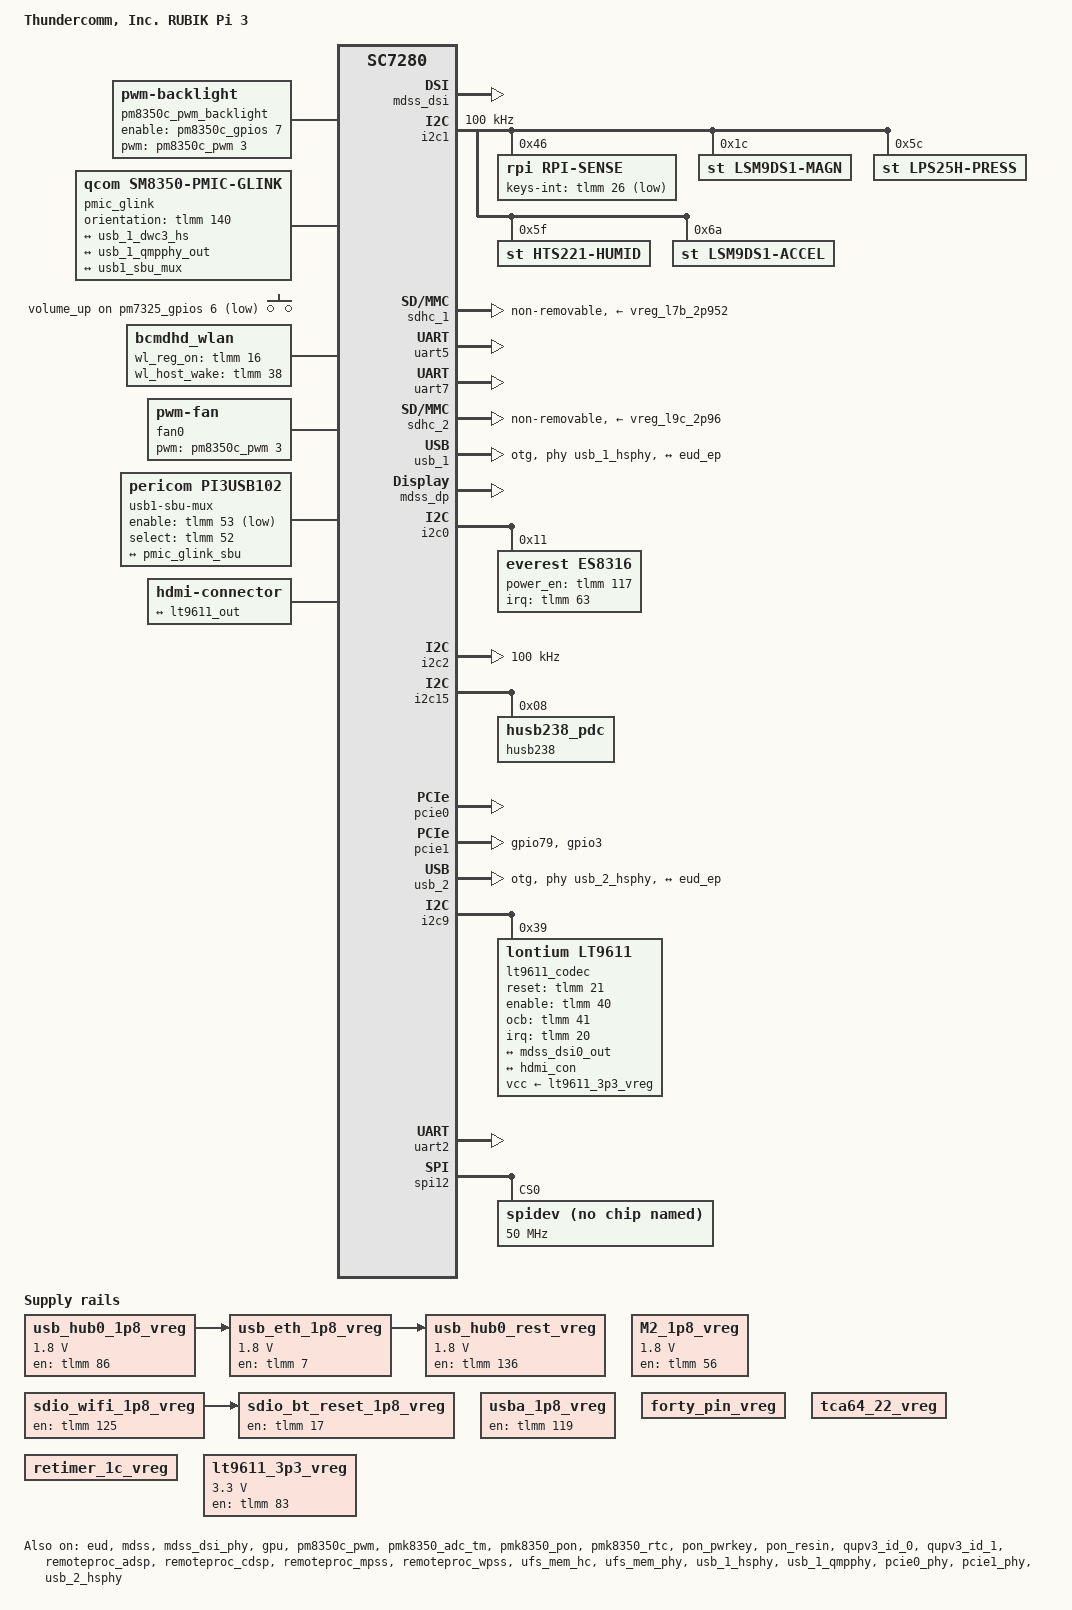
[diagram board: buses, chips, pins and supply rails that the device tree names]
// SPDX-License-Identifier: BSD-3-Clause
/*
 * Copyright (c) 2024, Thundercomm All rights reserved.
 */
#define PM7250B_SID 8
#define PM7250B_SID1 9

#include <dt-bindings/iio/qcom,spmi-adc7-pm7325.h>
#include <dt-bindings/iio/qcom,spmi-adc7-pmk8350.h>
#include <dt-bindings/input/linux-event-codes.h>
#include <dt-bindings/leds/common.h>
#include <dt-bindings/pinctrl/qcom,pmic-gpio.h>
#include <dt-bindings/regulator/qcom,rpmh-regulator.h>
#include "qcm6490.dtsi"
#include "pm7250b.dtsi"
#include "pm7325.dtsi"
#include "pm8350c.dtsi"
#include "pmk8350.dtsi"
#include "qcm6490-addons.dtsi"

/ {
	aliases {
		serial0 = &uart5;
		bluetooth0 = &bluetooth;
	};

	pm8350c_pwm_backlight: backlight {
		compatible = "pwm-backlight";
		pwms = <&pm8350c_pwm 3 65535>;
		enable-gpios = <&pm8350c_gpios 7 GPIO_ACTIVE_HIGH>;
		pinctrl-0 = <&pmic_lcd_bl_en>;
		pinctrl-names = "default";
	};

	chosen {
		stdout-path = "serial0:115200n8";
	};

	lcd_disp_bias: regulator-lcd-disp-bias {
		compatible = "regulator-fixed";
		regulator-name = "lcd_disp_bias";
		regulator-min-microvolt = <5500000>;
		regulator-max-microvolt = <5500000>;
		gpio = <&pm7250b_gpios 2 GPIO_ACTIVE_HIGH>;
		enable-active-high;
		pinctrl-0 = <&lcd_disp_bias_en>;
		pinctrl-names = "default";
	};

	pmic-glink {
		compatible = "qcom,sm8350-pmic-glink", "qcom,pmic-glink";
		#address-cells = <1>;
		#size-cells = <0>;
		orientation-gpios = <&tlmm 140 GPIO_ACTIVE_HIGH>;
		qcom,thermal-mitigation = <3000000 1500000 1000000 500000>;

		connector@0 {
			compatible = "usb-c-connector";
			reg = <0>;
			power-role = "dual";
			data-role = "dual";

			ports {
				#address-cells = <1>;
				#size-cells = <0>;

				port@0 {
					reg = <0>;

					pmic_glink_hs_in: endpoint {
						remote-endpoint = <&eud_con>;
					};
				};

				port@1 {
					reg = <1>;

					pmic_glink_ss_in: endpoint {
						remote-endpoint = <&usb_1_qmpphy_out>;
					};
				};

				port@2 {
					reg = <2>;

					pmic_glink_sbu: endpoint {
						remote-endpoint = <&fsa4480_sbu_mux>;
					};
				};
			};
		};
	};

	sound: sound {
		compatible = "qcom,qcm6490-sndcard";
		model = "qcm6490-idp-snd-card";

		// audio-routing =
		// 	"SpkrLeft IN", "WSA_SPK1 OUT",
		// 	"SpkrRight IN", "WSA_SPK2 OUT",
		// 	"IN1_HPHL", "HPHL_OUT",
		// 	"IN2_HPHR", "HPHR_OUT",
		// 	"AMIC2", "MIC BIAS2",
		// 	"TX DMIC0", "MIC BIAS1",
		// 	"TX DMIC1", "MIC BIAS2",
		// 	"TX DMIC2", "MIC BIAS3",
		// 	"TX SWR_ADC1", "ADC2_OUTPUT",
		// 	"VA DMIC0", "VA MIC BIAS3",
		// 	"VA DMIC1", "VA MIC BIAS3",
		// 	"VA DMIC2", "VA MIC BIAS1",
		// 	"VA DMIC3", "VA MIC BIAS1";

			#address-cells = <1>;
			#size-cells = <0>;

		wsa-dai-link {
			link-name = "CODEC_DMA-LPAIF_WSA-RX-0";

			cpu {
				sound-dai = <&q6apmbedai WSA_CODEC_DMA_RX_0>;
			};

			codec {
				sound-dai = <&left_spkr>, <&right_spkr>, <&swr2 0>,
					    <&lpass_wsa_macro 0>;
			};
		};

		wcd-playback-dai-link {
			link-name = "CODEC_DMA-LPAIF_RXTX-RX-0";

			cpu {
				sound-dai = <&q6apmbedai RX_CODEC_DMA_RX_0>;
			};

			codec {
				sound-dai = <&wcd9370 0>, <&swr0 0>, <&lpass_rx_macro 0>;
			};
		};

		wcd-capture-dai-link {
			link-name = "CODEC_DMA-LPAIF_RXTX-TX-3";

			cpu {
				sound-dai = <&q6apmbedai TX_CODEC_DMA_TX_3>;
			};

			codec {
				sound-dai = <&wcd9370 1>, <&swr1 0>, <&lpass_tx_macro 0>;
			};
		};

		va-dai-link {
			link-name = "CODEC_DMA-LPAIF_VA-TX-0";

			cpu {
				sound-dai = <&q6apmbedai VA_CODEC_DMA_TX_0>;
			};

			codec {
				sound-dai = <&lpass_va_macro 0>;
			};
		};

		vi-feedback-dai-link {
			link-name = "CODEC_DMA-LPAIF_WSA-TX-0";

			cpu {
				sound-dai = <&q6apmbedai WSA_CODEC_DMA_TX_0>;
			};

			codec {
				sound-dai = <&swr2 6>, <&lpass_wsa_macro 2>;
			};
		};
	};

	thermal-zones {
		quiet-thermal {
			polling-delay-passive = <0>;
			polling-delay = <0>;
			thermal-sensors = <&pmk8350_adc_tm 1>;

			trips {
				active-config0 {
					temperature = <125000>;
					hysteresis = <1000>;
					type = "passive";
				};
			};
		};

		sdm-skin-thermal {
			polling-delay-passive = <0>;
			polling-delay = <0>;
			thermal-sensors = <&pmk8350_adc_tm 3>;

			trips {
				active-config0 {
					temperature = <125000>;
					hysteresis = <1000>;
					type = "passive";
				};
			};
		};

		xo-thermal {
			polling-delay-passive = <0>;
			polling-delay = <0>;
			thermal-sensors = <&pmk8350_adc_tm 0>;

			trips {
				active-config0 {
					temperature = <125000>;
					hysteresis = <1000>;
					type = "passive";
				};
			};
		};
	};

	wcd9370: audio-codec-0 {
		compatible = "qcom,wcd9370-codec";

		pinctrl-names = "default", "sleep";
		pinctrl-0 = <&wcd_reset_n>;
		pinctrl-1 = <&wcd_reset_n_sleep>;

		reset-gpios = <&tlmm 83 GPIO_ACTIVE_LOW>;

		vdd-buck-supply = <&vreg_l17b_1p7>;
		vdd-rxtx-supply = <&vreg_l18b_1p8>;
		vdd-px-supply = <&vreg_l18b_1p8>;
		vdd-mic-bias-supply = <&vreg_bob_3p296>;

		qcom,micbias1-microvolt = <1800000>;
		qcom,micbias2-microvolt = <1800000>;
		qcom,micbias3-microvolt = <1800000>;

		qcom,rx-device = <&wcd937x_rx>;
		qcom,tx-device = <&wcd937x_tx>;

		#sound-dai-cells = <1>;
	};

	gpio-keys {
		compatible = "gpio-keys";
		label = "gpio-keys";

		pinctrl-names = "default";
		pinctrl-0 = <&key_vol_up_default>;

		key-volume-up {
			label = "volume_up";
			gpios = <&pm7325_gpios 6 GPIO_ACTIVE_LOW>;
			linux,input-type = <1>;
			linux,code = <KEY_VOLUMEUP>;
			wakeup-source;
			debounce-interval = <15>;
			linux,can-disable;
		};
	};
};

&apps_rsc {
	regulators-0 {
		compatible = "qcom,pm7325-rpmh-regulators";
		qcom,pmic-id = "b";

		vreg_s1b_1p872: smps1 {
			regulator-name = "vreg_s1b_1p872";
			regulator-min-microvolt = <1856000>;
			regulator-max-microvolt = <2040000>;
		};

		vreg_s7b_0p972: smps7 {
			regulator-name = "vreg_s7b_0p972";
			regulator-min-microvolt = <535000>;
			regulator-max-microvolt = <1120000>;
		};

		vreg_s8b_1p272: smps8 {
			regulator-name = "vreg_s8b_1p272";
			regulator-min-microvolt = <1256000>;
			regulator-max-microvolt = <1500000>;
			regulator-initial-mode = <RPMH_REGULATOR_MODE_RET>;
		};

		vreg_l1b_0p912: ldo1 {
			regulator-name = "vreg_l1b_0p912";
			regulator-min-microvolt = <912000>;
			regulator-max-microvolt = <925000>;
			regulator-initial-mode = <RPMH_REGULATOR_MODE_HPM>;
		};

		vreg_l2b_3p072: ldo2 {
			regulator-name = "vreg_l2b_3p072";
			regulator-min-microvolt = <2700000>;
			regulator-max-microvolt = <3544000>;
			regulator-initial-mode = <RPMH_REGULATOR_MODE_HPM>;
		};

		vreg_l6b_1p2: ldo6 {
			regulator-name = "vreg_l6b_1p2";
			regulator-min-microvolt = <1140000>;
			regulator-max-microvolt = <1260000>;
			regulator-initial-mode = <RPMH_REGULATOR_MODE_HPM>;
		};

		vreg_l7b_2p952: ldo7 {
			regulator-name = "vreg_l7b_2p952";
			regulator-min-microvolt = <2960000>;
			regulator-max-microvolt = <2960000>;
			regulator-initial-mode = <RPMH_REGULATOR_MODE_HPM>;
		};

		vreg_l8b_0p904: ldo8 {
			regulator-name = "vreg_l8b_0p904";
			regulator-min-microvolt = <870000>;
			regulator-max-microvolt = <970000>;
			regulator-initial-mode = <RPMH_REGULATOR_MODE_HPM>;
		};

		vreg_l9b_1p2: ldo9 {
			regulator-name = "vreg_l9b_1p2";
			regulator-min-microvolt = <1080000>;
			regulator-max-microvolt = <1304000>;
			regulator-initial-mode = <RPMH_REGULATOR_MODE_HPM>;
		};

		vreg_l11b_1p504: ldo11 {
			regulator-name = "vreg_l11b_1p504";
			regulator-min-microvolt = <1504000>;
			regulator-max-microvolt = <2000000>;
			regulator-initial-mode = <RPMH_REGULATOR_MODE_HPM>;
		};

		vreg_l12b_0p751: ldo12 {
			regulator-name = "vreg_l12b_0p751";
			regulator-min-microvolt = <751000>;
			regulator-max-microvolt = <824000>;
			regulator-initial-mode = <RPMH_REGULATOR_MODE_HPM>;
		};

		vreg_l13b_0p53: ldo13 {
			regulator-name = "vreg_l13b_0p53";
			regulator-min-microvolt = <530000>;
			regulator-max-microvolt = <824000>;
			regulator-initial-mode = <RPMH_REGULATOR_MODE_HPM>;
		};

		vreg_l14b_1p08: ldo14 {
			regulator-name = "vreg_l14b_1p08";
			regulator-min-microvolt = <1080000>;
			regulator-max-microvolt = <1304000>;
			regulator-initial-mode = <RPMH_REGULATOR_MODE_HPM>;
		};

		vreg_l15b_0p765: ldo15 {
			regulator-name = "vreg_l15b_0p765";
			regulator-min-microvolt = <765000>;
			regulator-max-microvolt = <1020000>;
			regulator-initial-mode = <RPMH_REGULATOR_MODE_HPM>;
		};

		vreg_l16b_1p1: ldo16 {
			regulator-name = "vreg_l16b_1p1";
			regulator-min-microvolt = <1100000>;
			regulator-max-microvolt = <1300000>;
			regulator-initial-mode = <RPMH_REGULATOR_MODE_HPM>;
		};

		vreg_l17b_1p7: ldo17 {
			regulator-name = "vreg_l17b_1p7";
			regulator-min-microvolt = <1700000>;
			regulator-max-microvolt = <1900000>;
			regulator-initial-mode = <RPMH_REGULATOR_MODE_HPM>;
		};

		vreg_l18b_1p8: ldo18 {
			regulator-name = "vreg_l18b_1p8";
			regulator-min-microvolt = <1800000>;
			regulator-max-microvolt = <2000000>;
			regulator-initial-mode = <RPMH_REGULATOR_MODE_HPM>;
		};

		vreg_l19b_1p8: ldo19 {
			regulator-name = "vreg_l19b_1p8";
			regulator-min-microvolt = <1800000>;
			regulator-max-microvolt = <1800000>;
			regulator-initial-mode = <RPMH_REGULATOR_MODE_HPM>;
		};
	};

	regulators-1 {
		compatible = "qcom,pm8350c-rpmh-regulators";
		qcom,pmic-id = "c";

		vreg_s1c_2p19: smps1 {
			regulator-name = "vreg_s1c_2p19";
			regulator-min-microvolt = <2190000>;
			regulator-max-microvolt = <2210000>;
			regulator-initial-mode = <RPMH_REGULATOR_MODE_HPM>;
		};

		vreg_s9c_1p084: smps9 {
			regulator-name = "vreg_s9c_1p084";
			regulator-min-microvolt = <1010000>;
			regulator-max-microvolt = <1170000>;
			regulator-initial-mode = <RPMH_REGULATOR_MODE_HPM>;
		};

		vreg_l1c_1p8: ldo1 {
			regulator-name = "vreg_l1c_1p8";
			regulator-min-microvolt = <1800000>;
			regulator-max-microvolt = <1980000>;
			regulator-initial-mode = <RPMH_REGULATOR_MODE_HPM>;
		};

		vreg_l2c_1p62: ldo2 {
			regulator-name = "vreg_l2c_1p62";
			regulator-min-microvolt = <1620000>;
			regulator-max-microvolt = <1980000>;
			regulator-initial-mode = <RPMH_REGULATOR_MODE_HPM>;
		};

		vreg_l3c_2p8: ldo3 {
			regulator-name = "vreg_l3c_2p8";
			regulator-min-microvolt = <2800000>;
			regulator-max-microvolt = <3540000>;
			regulator-initial-mode = <RPMH_REGULATOR_MODE_HPM>;
		};

		vreg_l4c_1p62: ldo4 {
			regulator-name = "vreg_l4c_1p62";
			regulator-min-microvolt = <1620000>;
			regulator-max-microvolt = <3300000>;
			regulator-initial-mode = <RPMH_REGULATOR_MODE_HPM>;
		};

		vreg_l5c_1p62: ldo5 {
			regulator-name = "vreg_l5c_1p62";
			regulator-min-microvolt = <1620000>;
			regulator-max-microvolt = <3300000>;
			regulator-initial-mode = <RPMH_REGULATOR_MODE_HPM>;
		};

		vreg_l6c_2p96: ldo6 {
			regulator-name = "vreg_l6c_2p96";
			regulator-min-microvolt = <1800000>;
			regulator-max-microvolt = <2950000>;
			regulator-initial-mode = <RPMH_REGULATOR_MODE_HPM>;
		};

		vreg_l7c_3p0: ldo7 {
			regulator-name = "vreg_l7c_3p0";
			regulator-min-microvolt = <3000000>;
			regulator-max-microvolt = <3544000>;
			regulator-initial-mode = <RPMH_REGULATOR_MODE_HPM>;
		};

		vreg_l8c_1p62: ldo8 {
			regulator-name = "vreg_l8c_1p62";
			regulator-min-microvolt = <1620000>;
			regulator-max-microvolt = <2000000>;
			regulator-initial-mode = <RPMH_REGULATOR_MODE_HPM>;
		};

		vreg_l9c_2p96: ldo9 {
			regulator-name = "vreg_l9c_2p96";
			regulator-min-microvolt = <2960000>;
			regulator-max-microvolt = <2960000>;
			regulator-initial-mode = <RPMH_REGULATOR_MODE_HPM>;
		};

		vreg_l10c_0p88: ldo10 {
			regulator-name = "vreg_l10c_0p88";
			regulator-min-microvolt = <880000>;
			regulator-max-microvolt = <1050000>;
			regulator-initial-mode = <RPMH_REGULATOR_MODE_HPM>;
		};

		vreg_l11c_2p8: ldo11 {
			regulator-name = "vreg_l11c_2p8";
			regulator-min-microvolt = <2800000>;
			regulator-max-microvolt = <3544000>;
			regulator-initial-mode = <RPMH_REGULATOR_MODE_HPM>;
		};

		vreg_l12c_1p65: ldo12 {
			regulator-name = "vreg_l12c_1p65";
			regulator-min-microvolt = <1650000>;
			regulator-max-microvolt = <2000000>;
			regulator-initial-mode = <RPMH_REGULATOR_MODE_HPM>;
		};

		vreg_l13c_2p7: ldo13 {
			regulator-name = "vreg_l13c_2p7";
			regulator-min-microvolt = <2700000>;
			regulator-max-microvolt = <3544000>;
			regulator-initial-mode = <RPMH_REGULATOR_MODE_HPM>;
		};

		vreg_bob_3p296: bob {
			regulator-name = "vreg_bob_3p296";
			regulator-min-microvolt = <3008000>;
			regulator-max-microvolt = <3960000>;
		};
	};
};

&eud {
	usb-role-switch;
	status = "okay";
};

&eud_con {
	remote-endpoint = <&pmic_glink_hs_in>;
};

&eud_ep {
	remote-endpoint = <&usb_1_dwc3_hs>;
};

&mdss {
	status = "okay";
};

&mdss_dsi {
	vdda-supply = <&vreg_l6b_1p2>;
	status = "okay";

	panel@0 {
		compatible = "novatek,nt36672e";
		reg = <0>;

		reset-gpios = <&tlmm 44 GPIO_ACTIVE_HIGH>;

		vddi-supply = <&vreg_l8c_1p62>;
		avdd-supply = <&lcd_disp_bias>;
		avee-supply = <&lcd_disp_bias>;

		backlight = <&pm8350c_pwm_backlight>;

		port {
			panel0_in: endpoint {
				remote-endpoint = <&mdss_dsi0_out>;
			};
		};
	};
};

&mdss_dsi0_out {
	remote-endpoint = <&panel0_in>;
	data-lanes = <0 1 2 3>;
};

&mdss_dsi_phy {
	vdds-supply = <&vreg_l10c_0p88>;
	status = "okay";
};

&gpi_dma0 {
	status = "okay";
};

&gpi_dma1 {
	status = "okay";
};

&i2c1 {
	clock-frequency = <100000>;
	status = "okay";

	typec-mux@42 {
		compatible = "fcs,fsa4480";
		reg = <0x42>;
		interrupts-extended = <&tlmm 2 IRQ_TYPE_LEVEL_LOW>;
		vcc-supply = <&vreg_bob_3p296>;
		mode-switch;
		orientation-switch;
		svid = /bits/ 16 <0xff01>;

		ports {
			#address-cells = <1>;
			#size-cells = <0>;

			port@0 {
				reg = <0>;

				fsa4480_sbu_mux: endpoint {
					remote-endpoint = <&pmic_glink_sbu>;
				};
			};
		};
	};
};

&lpasscc {
	status = "disabled";
};

&lpass_dmic01_clk {
	drive-strength = <8>;
	bias-disable;
};

&lpass_dmic01_data {
	bias-pull-down;
};

&lpass_dmic23_clk {
	drive-strength = <8>;
	bias-disable;
};

&lpass_dmic23_data {
	bias-pull-down;
};

&lpass_rx_swr_clk {
	drive-strength = <2>;
	slew-rate = <1>;
	bias-disable;
};

&lpass_rx_swr_data {
	drive-strength = <2>;
	slew-rate = <1>;
	bias-bus-hold;
};

&lpass_tx_swr_clk {
	drive-strength = <2>;
	slew-rate = <1>;
	bias-disable;
};

&lpass_tx_swr_data {
	drive-strength = <2>;
	slew-rate = <1>;
	bias-bus-hold;
};

&lpass_wsa_swr_clk {
	drive-strength = <2>;
	slew-rate = <1>;
	bias-disable;
};

&lpass_wsa_swr_data {
	drive-strength = <2>;
	slew-rate = <1>;
	bias-bus-hold;
};

&pm7325_gpios {
	key_vol_up_default: key-vol-up-state {
		pins = "gpio6";
		function = "normal";
		input-enable;
		bias-pull-up;
		power-source = <0>;
		qcom,drive-strength = <3>;
	};
};

&gpu {
	status = "okay";
};

&gpu_zap_shader {
	firmware-name = "qcom/qcm6490/a660_zap.mbn";
};

&pm7250b_gpios {
	lcd_disp_bias_en: lcd-disp-bias-en-state {
		pins = "gpio2";
		function = "func1";
		bias-disable;
		qcom,drive-strength = <PMIC_GPIO_STRENGTH_LOW>;
		input-disable;
		output-enable;
		power-source = <0>;
	};
};

&pm8350c_gpios {
	pmic_lcd_bl_en: pmic-lcd-bl-en-state {
		pins = "gpio7";
		function = "normal";
		bias-disable;
		qcom,drive-strength = <PMIC_GPIO_STRENGTH_LOW>;
		output-low;
		power-source = <0>;
	};

	pmic_lcd_bl_pwm: pmic-lcd-bl-pwm-state {
		pins = "gpio8";
		function = "func1";
		bias-disable;
		qcom,drive-strength = <PMIC_GPIO_STRENGTH_LOW>;
		output-low;
		power-source = <0>;
	};
};

&pm8350c_pwm {
	#address-cells = <1>;
	#size-cells = <0>;
	pinctrl-0 = <&pmic_lcd_bl_pwm>;
	pinctrl-names = "default";
	status = "okay";

	led@1 {
		reg = <1>;
		color = <LED_COLOR_ID_RED>;
		label = "red";
	};

	led@2 {
		reg = <2>;
		color = <LED_COLOR_ID_GREEN>;
		label = "green";
	};

	led@3 {
		reg = <3>;
		color = <LED_COLOR_ID_BLUE>;
		label = "blue";
	};
};

&pmk8350_adc_tm {
	status = "okay";

	xo-therm@0 {
		reg = <0>;
		io-channels = <&pmk8350_vadc PMK8350_ADC7_AMUX_THM1_100K_PU>;
		qcom,ratiometric;
		qcom,hw-settle-time-us = <200>;
	};

	quiet-therm@1 {
		reg = <1>;
		io-channels = <&pmk8350_vadc PM7325_ADC7_AMUX_THM1_100K_PU>;
		qcom,ratiometric;
		qcom,hw-settle-time-us = <200>;
	};

	sdm-skin-therm@3 {
		reg = <3>;
		io-channels = <&pmk8350_vadc PM7325_ADC7_AMUX_THM3_100K_PU>;
		qcom,ratiometric;
		qcom,hw-settle-time-us = <200>;
	};
};

&pmk8350_pon {
	status = "okay";
};

&pmk8350_rtc {
	status = "okay";
};

&pmk8350_vadc {
	channel@44 {
		reg = <PMK8350_ADC7_AMUX_THM1_100K_PU>;
		label = "xo_therm";
		qcom,hw-settle-time = <200>;
		qcom,pre-scaling = <1 1>;
		qcom,ratiometric;
	};

	channel@144 {
		reg = <PM7325_ADC7_AMUX_THM1_100K_PU>;
		qcom,ratiometric;
		qcom,hw-settle-time = <200>;
		qcom,pre-scaling = <1 1>;
		label = "pm7325_quiet_therm";
	};

	channel@146 {
		reg = <PM7325_ADC7_AMUX_THM3_100K_PU>;
		qcom,ratiometric;
		qcom,hw-settle-time = <200>;
		qcom,pre-scaling = <1 1>;
		label = "pm7325_sdm_skin_therm";
	};

	pmk8350-die-temp@3 {
		reg = <PMK8350_ADC7_DIE_TEMP>;
		label = "pmk8350_die_temp";
		qcom,pre-scaling = <1 1>;
	};
};

&pon_pwrkey {
	status = "okay";
};

&pon_resin {
	linux,code = <KEY_VOLUMEDOWN>;
	status = "okay";
};

&qup_uart5_rx {
	drive-strength = <2>;
	bias-pull-up;
};

&qup_uart5_tx {
	drive-strength = <2>;
	bias-disable;
};

&qup_uart7_cts {
	/*
	 * Configure a bias-bus-hold on CTS to lower power
	 * usage when Bluetooth is turned off. Bus hold will
	 * maintain a low power state regardless of whether
	 * the Bluetooth module drives the pin in either
	 * direction or leaves the pin fully unpowered.
	 */
	bias-bus-hold;
};

&qup_uart7_rts {
	/* We'll drive RTS, so no pull */
	drive-strength = <2>;
	bias-disable;
};

&qup_uart7_rx {
	/*
	 * Configure a pull-up on RX. This is needed to avoid
	 * garbage data when the TX pin of the Bluetooth module is
	 * in tri-state (module powered off or not driving the
	 * signal yet).
	 */
	bias-pull-up;
};

&qup_uart7_tx {
	/* We'll drive TX, so no pull */
	drive-strength = <2>;
	bias-disable;
};

&qupv3_id_0 {
	status = "okay";
};

&qupv3_id_1 {
	status = "okay";
};

&remoteproc_adsp {
	firmware-name = "qcom/qcm6490/adsp.mdt";
	status = "okay";
};

&remoteproc_cdsp {
	firmware-name = "qcom/qcm6490/cdsp.mdt";
	status = "okay";
};

&remoteproc_mpss {
	firmware-name = "qcom/qcm6490/modem.mdt";
	status = "okay";
};

&remoteproc_wpss {
	firmware-name = "qcom/qcm6490/wpss.mdt";
	status = "okay";
};

&sdc1_clk {
	bias-disable;
	drive-strength = <16>;
};

&sdc1_cmd {
	bias-pull-up;
	drive-strength = <10>;
};

&sdc1_data {
	bias-pull-up;
	drive-strength = <10>;
};

&sdc1_rclk {
	bias-pull-down;
};

&swr2 {
	qcom,din-ports = <0>;
	qcom,dout-ports = <8>;

	left_spkr: speaker@0,1 {
		compatible = "sdw10217020200";
		reg = <0 1>;
		powerdown-gpios = <&tlmm 63 GPIO_ACTIVE_LOW>;
		#sound-dai-cells = <0>;
		sound-name-prefix = "SpkrLeft";
		#thermal-sensor-cells = <0>;
		vdd-supply = <&vreg_l18b_1p8>;
		qcom,port-mapping = <1 2 3 7>;
	};

	right_spkr: speaker@0,2 {
		compatible = "sdw10217020200";
		reg = <0 2>;
		powerdown-gpios = <&tlmm 62 GPIO_ACTIVE_LOW>;
		#sound-dai-cells = <0>;
		sound-name-prefix = "SpkrRight";
		#thermal-sensor-cells = <0>;
		vdd-supply = <&vreg_l18b_1p8>;
		qcom,port-mapping = <4 5 6 8>;
	};
};

&sdhc_1 {
	non-removable;
	no-sd;
	no-sdio;

	vmmc-supply = <&vreg_l7b_2p952>;
	vqmmc-supply = <&vreg_l19b_1p8>;

	status = "okay";
};

&swr0 {
	wcd937x_rx: codec@0,4 {
		compatible = "sdw20217010a00";
		reg = <0 4>;
		qcom,rx-port-mapping = <1 2 3 4 5>;
	};
};

&swr1 {
	wcd937x_tx: codec@0,3 {
		compatible = "sdw20217010a00";
		reg = <0 3>;
		qcom,tx-port-mapping = <1 1 2 3>;
	};
};

&sdc2_clk {
	bias-disable;
	drive-strength = <16>;
};

&sdc2_cmd {
	bias-pull-up;
	drive-strength = <10>;
};

&sdc2_data {
	bias-pull-up;
	drive-strength = <10>;
};

&tlmm {
	bt_en: bt-en-state {
		pins = "gpio85";
		function = "gpio";
		output-low;
		bias-disable;
	};

	qup_uart7_sleep_cts: qup-uart7-sleep-cts-state {
		pins = "gpio28";
		function = "gpio";
		/*
		 * Configure a bias-bus-hold on CTS to lower power
		 * usage when Bluetooth is turned off. Bus hold will
		 * maintain a low power state regardless of whether
		 * the Bluetooth module drives the pin in either
		 * direction or leaves the pin fully unpowered.
		 */
		bias-bus-hold;
	};

	qup_uart7_sleep_rts: qup-uart7-sleep-rts-state {
		pins = "gpio29";
		function = "gpio";
		/*
		 * Configure pull-down on RTS. As RTS is active low
		 * signal, pull it low to indicate the BT SoC that it
		 * can wakeup the system anytime from suspend state by
		 * pulling RX low (by sending wakeup bytes).
		 */
		bias-pull-down;
	};

	qup_uart7_sleep_rx: qup-uart7-sleep-rx-state {
		pins = "gpio31";
		function = "gpio";
		/*
		 * Configure a pull-up on RX. This is needed to avoid
		 * garbage data when the TX pin of the Bluetooth module
		 * is floating which may cause spurious wakeups.
		 */
		bias-pull-up;
	};

	qup_uart7_sleep_tx: qup-uart7-sleep-tx-state {
		pins = "gpio30";
		function = "gpio";
		/*
		 * Configure pull-up on TX when it isn't actively driven
		 * to prevent BT SoC from receiving garbage during sleep.
		 */
		bias-pull-up;
	};

	sd_cd: sd-cd-state {
		pins = "gpio91";
		function = "gpio";
		bias-pull-up;
	};

	sw_ctrl: sw-ctrl-state {
		pins = "gpio86";
		function = "gpio";
		bias-pull-down;
	};

	wcd_reset_n: wcd-reset-n-state {
		pins = "gpio83";
		function = "gpio";
		drive-strength = <8>;
	};

	wcd_reset_n_sleep: wcd-reset-n-sleep-state {
		pins = "gpio83";
		function = "gpio";
		drive-strength = <8>;
		bias-disable;
	};
};

&uart5 {
	compatible = "qcom,geni-debug-uart";
	status = "okay";
};

&uart7 {
	status = "okay";
	/delete-property/interrupts;
	interrupts-extended = <&intc GIC_SPI 608 IRQ_TYPE_LEVEL_HIGH>,
				<&tlmm 31 IRQ_TYPE_EDGE_FALLING>;
	pinctrl-names = "default", "sleep";
	pinctrl-1 = <&qup_uart7_sleep_cts>, <&qup_uart7_sleep_rts>,
			<&qup_uart7_sleep_tx>, <&qup_uart7_sleep_rx>;

	bluetooth: bluetooth {
		compatible = "qcom,wcn6750-bt";
		pinctrl-names = "default";
		pinctrl-0 = <&bt_en>, <&sw_ctrl>;
		enable-gpios = <&tlmm 85 GPIO_ACTIVE_HIGH>;
		swctrl-gpios = <&tlmm 86 GPIO_ACTIVE_HIGH>;
		vddaon-supply = <&vreg_s7b_0p972>;
		vddbtcxmx-supply = <&vreg_s7b_0p972>;
		vddrfacmn-supply = <&vreg_s7b_0p972>;
		vddrfa0p8-supply = <&vreg_s7b_0p972>;
		vddrfa1p7-supply = <&vreg_s1b_1p872>;
		vddrfa1p2-supply = <&vreg_s8b_1p272>;
		vddrfa2p2-supply = <&vreg_s1c_2p19>;
		vddasd-supply = <&vreg_l11c_2p8>;
		max-speed = <3200000>;
	};
};

&ufs_mem_hc {
	reset-gpios = <&tlmm 175 GPIO_ACTIVE_LOW>;
	vcc-supply = <&vreg_l7b_2p952>;
	vcc-max-microamp = <800000>;
	vccq-supply = <&vreg_l9b_1p2>;
	vccq-max-microamp = <900000>;
	vccq2-supply = <&vreg_l9b_1p2>;
	vccq2-max-microamp = <900000>;

	status = "okay";
};

&ufs_mem_phy {
	vdda-phy-supply = <&vreg_l10c_0p88>;
	vdda-pll-supply = <&vreg_l6b_1p2>;

	status = "okay";
};

&sdhc_2 {
	status = "okay";

	pinctrl-0 = <&sdc2_clk>, <&sdc2_cmd>, <&sdc2_data>, <&sd_cd>;
	pinctrl-1 = <&sdc2_clk_sleep>, <&sdc2_cmd_sleep>, <&sdc2_data_sleep>, <&sd_cd>;

	vmmc-supply = <&vreg_l9c_2p96>;
	vqmmc-supply = <&vreg_l6c_2p96>;

	cd-gpios = <&tlmm 91 GPIO_ACTIVE_LOW>;
};

/delete-node/ &usb_1_dwc3;

&usb_1 {

	reg = <0x0 0x0a600000 0x0 0x200000>;

	interrupts-extended = <&intc GIC_SPI 133 IRQ_TYPE_LEVEL_HIGH>,
			      <&intc GIC_SPI 131 IRQ_TYPE_LEVEL_HIGH>,
			      <&pdc 14 IRQ_TYPE_LEVEL_HIGH>,
			      <&pdc 15 IRQ_TYPE_EDGE_BOTH>,
			      <&pdc 17 IRQ_TYPE_EDGE_BOTH>;
	interrupt-names = "dwc_usb3",
			  "hs_phy_irq",
			  "dp_hs_phy_irq",
			  "dm_hs_phy_irq",
			  "ss_phy_irq";

	iommus = <&apps_smmu 0xe0 0x0>;
	snps,dis_u2_susphy_quirk;
	snps,dis_enblslpm_quirk;
	phys = <&usb_1_hsphy>, <&usb_1_qmpphy QMP_USB43DP_USB3_PHY>;
	phy-names = "usb2-phy", "usb3-phy";
	maximum-speed = "super-speed";

	dr_mode = "otg";
	usb-role-switch;
	qcom,enable-rt;
	wakeup-source;

	status = "okay";

	ports {
		#address-cells = <1>;
		#size-cells = <0>;


		port@0 {
			reg = <0>;
			usb_1_dwc3_hs: endpoint {
			};
		};
	};
};

&usb_1_dwc3_hs {
	remote-endpoint = <&eud_ep>;
};

&usb_1_hsphy {
	vdda-pll-supply = <&vreg_l10c_0p88>;
	vdda33-supply = <&vreg_l2b_3p072>;
	vdda18-supply = <&vreg_l1c_1p8>;
	qcom,hs-rise-fall-time-bp = <0>;
	qcom,squelch-detector-bp = <(-2090)>;
	qcom,hs-disconnect-bp = <1743>;
	qcom,hs-amplitude-bp = <1780>;
	qcom,hs-crossover-voltage-microvolt = <(-31000)>;
	qcom,hs-output-impedance-micro-ohms = <2600000>;

	status = "okay";
};

&usb_1_qmpphy {
	vdda-phy-supply = <&vreg_l6b_1p2>;
	vdda-pll-supply = <&vreg_l1b_0p912>;

	orientation-switch;
	status = "okay";
};

&usb_1_qmpphy_out {
	remote-endpoint = <&pmic_glink_ss_in>;
};

&vreg_l7b_2p952 {
	/delete-property/regulator-min-microvolt;
	/delete-property/regulator-max-microvolt;
	regulator-allow-set-load;
	regulator-allowed-modes = <RPMH_REGULATOR_MODE_LPM RPMH_REGULATOR_MODE_HPM>;
};

&vreg_l9b_1p2 {
	/delete-property/regulator-min-microvolt;
	/delete-property/regulator-max-microvolt;
	regulator-allow-set-load;
	regulator-allowed-modes = <RPMH_REGULATOR_MODE_LPM RPMH_REGULATOR_MODE_HPM>;
};

/ {
	pmic_glink: pmic-glink {
	};
};

&i2c1 {
	#address-cells = <1>;
	#size-cells = <0>;
	status = "okay";

	pm8008i_chip: pm8008i@8 {
		compatible = "qcom,i2c-pmic";
		reg = <0x8>;
		#address-cells = <1>;
		#size-cells = <0>;

		pinctrl-names = "default";
		pinctrl-0 = <&pm8008i_active>;

		pm8008-chip@900 {
			compatible = "qcom,pm8008-chip";
			reg = <0x900>;

			PM8008I_EN: qcom,pm8008-chip-en {
				regulator-name = "pm8008i-chip-en";
			};
		};
	};

	pm8008i_ldo: pm8008i@9 {
		compatible = "qcom,i2c-pmic";
		reg = <0x9>;
		#address-cells = <1>;
		#size-cells = <0>;

		qcom,pm8008i-regulator {
			compatible = "qcom,pm8008-regulator";
			#address-cells = <1>;
			#size-cells = <0>;

			pm8008_en-supply = <&PM8008I_EN>;
			vdd_l1_l2-supply = <&vreg_s8b_1p272>;
			vdd_l3_l4-supply = <&vreg_bob_3p296>;
			vdd_l5-supply = <&vreg_s1b_1p872>;
			vdd_l6-supply = <&vreg_bob_3p296>;
			vdd_l7-supply = <&vreg_bob_3p296>;

			L1I: PM8008I_L1: regulator@4000 {
				reg = <0x4000>;
				regulator-name = "pm8008i_l1";
				regulator-min-microvolt = <1000000>;
				regulator-max-microvolt = <1200000>;
				qcom,min-dropout-voltage = <160000>;
				qcom,hpm-min-load = <30000>;
			};

			L2I: PM8008I_L2: regulator@4100 {
				reg = <0x4100>;
				regulator-name = "pm8008i_l2";
				regulator-min-microvolt = <950000>;
				regulator-max-microvolt = <1150000>;
				qcom,min-dropout-voltage = <128000>;
				qcom,hpm-min-load = <30000>;
			};

			L3I: PM8008I_L3: regulator@4200 {
				reg = <0x4200>;
				regulator-name = "pm8008i_l3";
				regulator-min-microvolt = <2700000>;
				regulator-max-microvolt = <3000000>;
				qcom,min-dropout-voltage = <144000>;
			};

			L4I: PM8008I_L4: regulator@4300 {
				reg = <0x4300>;
				regulator-name = "pm8008i_l4";
				regulator-min-microvolt = <2700000>;
				regulator-max-microvolt = <2900000>;
				qcom,min-dropout-voltage = <128000>;
			};

			L5I: PM8008I_L5: regulator@4400 {
				reg = <0x4400>;
				regulator-name = "pm8008i_l5";
				regulator-min-microvolt = <1700000>;
				regulator-max-microvolt = <1900000>;
				qcom,min-dropout-voltage = <136000>;
			};

			L6I: PM8008I_L6: regulator@4500 {
				reg = <0x4500>;
				regulator-name = "pm8008i_l6";
				regulator-min-microvolt = <2700000>;
				regulator-max-microvolt = <2900000>;
				qcom,min-dropout-voltage = <128000>;
			};

			L7I: PM8008I_L7: regulator@4600 {
				reg = <0x4600>;
				regulator-name = "pm8008i_l7";
				regulator-min-microvolt = <2700000>;
				regulator-max-microvolt = <3000000>;
				qcom,min-dropout-voltage = <312000>;
			};
		};
	};

	pm8008j_chip: pm8008j@c {
		compatible = "qcom,i2c-pmic";
		reg = <0xc>;
		#address-cells = <1>;
		#size-cells = <0>;

		pinctrl-names = "default";
		pinctrl-0 = <&pm8008j_active>;

		pm8008-chip@900 {
			compatible = "qcom,pm8008-chip";
			reg = <0x900>;

			PM8008J_EN: qcom,pm8008-chip-en {
				regulator-name = "pm8008j-chip-en";
			};
		};
	};

	pm8008j_ldo: pm8008j@d {
		compatible = "qcom,i2c-pmic";
		reg = <0xd>;
		#address-cells = <1>;
		#size-cells = <0>;

		qcom,pm8008j-regulator {
			compatible = "qcom,pm8008-regulator";
			#address-cells = <1>;
			#size-cells = <0>;

			pm8008_en-supply = <&PM8008J_EN>;
			vdd_l1_l2-supply = <&vreg_s8b_1p272>;
			vdd_l3_l4-supply = <&vreg_s1b_1p872>;
			vdd_l5-supply = <&vreg_bob_3p296>;
			vdd_l6-supply = <&vreg_bob_3p296>;
			vdd_l7-supply = <&vreg_bob_3p296>;

			L1J: PM8008J_L1: regulator@4000 {
				reg = <0x4000>;
				regulator-name = "pm8008j_l1";
				regulator-min-microvolt = <950000>;
				regulator-max-microvolt = <1150000>;
				qcom,min-dropout-voltage = <96000>;
				qcom,hpm-min-load = <30000>;
			};

			L2J: PM8008J_L2: regulator@4100 {
				reg = <0x4100>;
				regulator-name = "pm8008j_l2";
				regulator-min-microvolt = <950000>;
				regulator-max-microvolt = <1250000>;
				qcom,min-dropout-voltage = <24000>;
				qcom,hpm-min-load = <30000>;
			};

			L3J: PM8008J_L3: regulator@4200 {
				reg = <0x4200>;
				regulator-name = "pm8008j_l3";
				regulator-min-microvolt = <1460000>;
				regulator-max-microvolt = <1800000>;
				qcom,min-dropout-voltage = <224000>;
			};

			L4J: PM8008J_L4: regulator@4300 {
				reg = <0x4300>;
				regulator-name = "pm8008j_l4";
				regulator-min-microvolt = <1504000>;
				regulator-max-microvolt = <1600000>;
				qcom,min-dropout-voltage = <0>;
			};

			L5J: PM8008J_L5: regulator@4400 {
				reg = <0x4400>;
				regulator-name = "pm8008j_l5";
				regulator-min-microvolt = <2700000>;
				regulator-max-microvolt = <2900000>;
				qcom,min-dropout-voltage = <104000>;
			};

			L6J: PM8008J_L6: regulator@4500 {
				reg = <0x4500>;
				regulator-name = "pm8008j_l6";
				regulator-min-microvolt = <2800000>;
				regulator-max-microvolt = <2800000>;
				qcom,min-dropout-voltage = <112000>;
			};

			L7J: PM8008J_L7: regulator@4600 {
				reg = <0x4600>;
				regulator-name = "pm8008j_l7";
				regulator-min-microvolt = <3000000>;
				regulator-max-microvolt = <3544000>;
				qcom,min-dropout-voltage = <96000>;
			};
		};
	};
};

&pm8350c_gpios {
	pm8008i-reset-state {
		pm8008i_active: pm8008i-active-pins {
			pins = "gpio3";
			function = "normal";
			bias-disable;
			output-high;
			power-source = <0>;
		};
	};

	pm8008j-reset-state {
		pm8008j_active: pm8008j-active-pins {
			pins = "gpio4";
			function = "normal";
			bias-disable;
			output-high;
			power-source = <0>;
		};
	};
};

&q6apmbedai {
	qcom,prmcc_clk = <&q6prmcc>;
};

&sound {
	pinctrl-names = "default", "stub_aif1_active", "stub_aif1_sleep";
	pinctrl-0 = <&mi2s0_data0_sleep>, <&mi2s0_data1_sleep>, <&mi2s0_mclk_sleep>,
				<&mi2s0_sclk_sleep>, <&mi2s0_ws_sleep>;
	pinctrl-1 = <&mi2s0_data0>, <&mi2s0_data1>, <&mi2s0_mclk>,
				<&mi2s0_sclk>, <&mi2s0_ws>;
	pinctrl-2 = <&mi2s0_data0_sleep>, <&mi2s0_data1_sleep>, <&mi2s0_mclk_sleep>,
				<&mi2s0_sclk_sleep>, <&mi2s0_ws_sleep>;

	mi2s-capture-dai-link {
		link-name = "MI2S-LPAIF-TX-PRIMARY";

		cpu {
			sound-dai = <&q6apmbedai PRIMARY_MI2S_TX>;
		};

		codec {
			sound-dai = <&msm_stub_codec 1>;
		};
	};

	mi2s-playback-dai-link {
		link-name = "MI2S-LPAIF-RX-PRIMARY";

		cpu {
			sound-dai = <&q6apmbedai PRIMARY_MI2S_RX>;
		};

		codec {
			sound-dai = <&msm_stub_codec 0>;
		};
	};

	tdm-capture-dai-link {
		link-name = "TDM-LPAIF-TX-PRIMARY";

		cpu {
			sound-dai = <&q6apmbedai PRIMARY_TDM_TX_0>;
		};

		codec {
			sound-dai = <&msm_stub_codec 1>;
		};
	};

	tdm-playback-dai-link {
		link-name = "TDM-LPAIF-RX-PRIMARY";

		cpu {
			sound-dai = <&q6apmbedai PRIMARY_TDM_RX_0>;
		};

		codec {
			sound-dai = <&msm_stub_codec 0>;
		};
	};
};

&tlmm {
	mi2s0_data0_sleep: mi2s0-data0-sleep {
		pins = "gpio98";
		function = "gpio";
		drive-strength = <2>;
		bias-pull-down;
		input-enable;
	};

	mi2s0_data1_sleep: mi2s0-data1-sleep {
		pins = "gpio99";
		function = "gpio";
		drive-strength = <2>;
		bias-pull-down;
		input-enable;
	};

	mi2s0_mclk_sleep: mi2s0-mclk-sleep {
		pins = "gpio96";
		function = "gpio";
		drive-strength = <2>;
		bias-pull-down;
		input-enable;
	};

	mi2s0_sclk_sleep: mi2s0-sclk-sleep {
		pins = "gpio97";
		function = "gpio";
		drive-strength = <2>;
		bias-pull-down;
		input-enable;
	};

	mi2s0_ws_sleep: mi2s0-ws-sleep {
		pins = "gpio100";
		function = "gpio";
		drive-strength = <2>;
		bias-pull-down;
		input-enable;
	};
};

/ {
	chosen {
		display_bootargs = "";
		enable_logo_Partition = "splash";
		stdout-path = "serial0:115200n8";
	};

	aliases {
		serial7 = &uart7;
		serial2 = &uart2;
		serial3 = &uart3;
		serial6 = &uart6;
		serial8 = &uart8;
		serial12 = &uart12;

	};

	usb_hub0_1p8_vreg: usb_hub0_1p8_vreg {
		compatible = "regulator-fixed";
		regulator-name = "usb_hub0_1p8_vreg";
		gpio = <&tlmm 86 0>;
		regulator-min-microvolt = <1800000>;
		regulator-max-microvolt = <1800000>;
		enable-active-high;
		regulator-always-on;
		regulator-enable-ramp-delay = <50000>;
	};

	usb_eth_1p8_vreg: usb_eth_1p8_vreg {
		compatible = "regulator-fixed";
		regulator-name = "usb_eth_1p8_vreg";
		gpio = <&tlmm 7 0>;
		vin-supply = <&usb_hub0_1p8_vreg>;
		regulator-min-microvolt = <1800000>;
		regulator-max-microvolt = <1800000>;
		enable-active-high;
		regulator-enable-ramp-delay = <50000>;
	};

	usb_hub0_rest_vreg: usb_hub0_rest_vreg {
		compatible = "regulator-fixed";
		regulator-name = "usb_hub0_rest_vreg";
		gpio = <&tlmm 136 0>;
		vin-supply = <&usb_eth_1p8_vreg>;
		regulator-min-microvolt = <1800000>;
		regulator-max-microvolt = <1800000>;
		enable-active-high;
		regulator-always-on;
		regulator-enable-ramp-delay = <50000>;
	};

	M2_1p8_vreg: M2_1p8_vreg {
		compatible = "regulator-fixed";
		regulator-name = "M2_1p8_vreg";
		gpio = <&tlmm 56 0>;
		regulator-min-microvolt = <1800000>;
		regulator-max-microvolt = <1800000>;
		enable-active-high;
		regulator-enable-ramp-delay = <50000>;
	};

	sdio_wifi_1p8_vreg: sdio_wifi_1p8_vreg {
		compatible = "regulator-fixed";
		regulator-name = "sdio_wifi_1p8_vreg";
		enable-active-high;
		gpio = <&tlmm 125 GPIO_ACTIVE_HIGH>;
		regulator-always-on;
		regulator-enable-ramp-delay = <50000>;
	};

	sdio_bt_reset_1p8_vreg: sdio_bt_reset_1p8_vreg {
		pinctrl-0 = <&wifi_reset_active>;
		pinctrl-names = "default";
		compatible = "regulator-fixed";
		regulator-name = "sdio_bt_reset_1p8_vreg";
		enable-active-high;
		gpio = <&tlmm 17 GPIO_ACTIVE_HIGH>;
		vin-supply = <&sdio_wifi_1p8_vreg>;
	};

	usba_1p8_vreg: usba_1p8_vreg {
		compatible = "regulator-fixed";
		regulator-name = "usba_1p8_vreg";
		enable-active-high;
		gpio = <&tlmm 119 GPIO_ACTIVE_HIGH>;
		regulator-enable-ramp-delay = <10000>;
	};

	bcmdhd_wlan: bcmdhd_wlan {
		compatible = "linux,bcmdhd_wlan";
		gpio_wl_reg_on = <&tlmm 16 GPIO_ACTIVE_HIGH>;
		gpio_wl_host_wake = <&tlmm 38 GPIO_ACTIVE_HIGH>;
	};

	pmic-glink {
		compatible = "qcom,sm8350-pmic-glink", "qcom,pmic-glink";
		#address-cells = <1>;
		#size-cells = <0>;
		orientation-gpios = <&tlmm 140 GPIO_ACTIVE_HIGH>;
		qcom,thermal-mitigation = <3000000 1500000 1000000 500000>;

		connector@0 {
			compatible = "usb-c-connector";
			reg = <0>;
			power-role = "dual";
			data-role = "dual";

			ports {
				#address-cells = <1>;
				#size-cells = <0>;

				port@0 {
					reg = <0>;
					pmic_glink_hs_in: endpoint {
						remote-endpoint = <&usb_1_dwc3_hs>;
					};
				};

				port@1 {
					reg = <1>;
					pmic_glink_ss_in: endpoint {
						remote-endpoint = <&usb_1_qmpphy_out>;
					};
				};

				port@2 {
					reg = <2>;
					pmic_glink_sbu: endpoint {
						remote-endpoint = <&usb1_sbu_mux>;
					};
				};
			};
		};
	};

	fan0: pwm-fan {
		compatible = "pwm-fan";
		pwms = <&pm8350c_pwm 3 1000000>;
		pinctrl-names = "default";
		pinctrl-0 = <&fan_pwm_out_default>;
		#cooling-cells = <2>;
		cooling-min-state = <0>;
		cooling-max-state = <2>;
		cooling-levels = <0 100 255>;
	};

	forty_pin_vreg: forty_pin_vreg {
		pinctrl-names = "default";
		pinctrl-0 = <&io_level_selection_3v3>,<&io_level_selection_5v0>,
				<&gpio4_active>,<&gpio5_active>,<&gpio8_active>,
				<&gpio9_active>,<&gpio10_active>,<&gpio11_active>,
				<&gpio12_active>,<&gpio24_active>,<&gpio25_active>,
				<&gpio26_active>,<&gpio27_active>,<&gpio32_active>,
				<&gpio33_active>,<&gpio34_active>,<&gpio35_active>,
				<&gpio44_active>,<&gpio48_active>,<&gpio49_active>,
				<&gpio50_active>,<&gpio51_active>,<&gpio55_active>,
				<&gpio101_active>,<&gpio102_active>,<&gpio103_active>,
				<&gpio104_active>,<&gpio105_active>;
		compatible = "regulator-fixed";
	};
};

&qupv3_id_0 {
	dummy = <&forty_pin_vreg>;
};

&qupv3_id_1 {
	dummy = <&qupv3_id_0>;
};

&mdss_dp {
	status = "okay";
};

&mdss_dp_out {
	data-lanes = <0 1>;
	remote-endpoint = <&usb_1_qmpphy_dp_in>;
};

&usb_1_qmpphy_out {
	remote-endpoint = <&pmic_glink_ss_in>;
};

&usb_1_qmpphy_dp_in {
	remote-endpoint = <&mdss_dp_out>;
};

&tlmm {
	usb1_sbu_default: usb1-sbu-state {
		oe-n-pins {
			pins = "gpio53";
			function = "gpio";
			bias-disable;
			drive-strength = <16>;
			output-high;
		};
		sel-pins {
			pins = "gpio52";
			function = "gpio";
			bias-disable;
			drive-strength = <16>;
		};
	};
};

/ {
	usb1-sbu-mux {
		compatible = "pericom,pi3usb102", "gpio-sbu-mux";
		enable-gpios = <&tlmm 53 GPIO_ACTIVE_LOW>;
		select-gpios = <&tlmm 52 GPIO_ACTIVE_HIGH>;
		pinctrl-names = "default";
		pinctrl-0 = <&usb1_sbu_default>;
		mode-switch;
		orientation-switch;
		port {
			usb1_sbu_mux: endpoint {
				remote-endpoint = <&pmic_glink_sbu>;
			};
		};
	};
};

&tlmm {
	/delete-property/ gpio-reserved-ranges;

	gpio4_active: gpio4_active {
		pins = "gpio4";
		function = "gpio";
		drive-strength = <2>;
		bias-disable;
	};

	gpio5_active: gpio5_active {
		pins = "gpio5";
		function = "gpio";
		drive-strength = <2>;
		bias-disable;
	};

	gpio8_active: gpio8_active {
		pins = "gpio8";
		function = "gpio";
		drive-strength = <2>;
		bias-disable;
	};

	gpio9_active: gpio9_active {
		pins = "gpio9";
		function = "gpio";
		drive-strength = <2>;
		bias-disable;
	};

	gpio10_active: gpio10_active {
		pins = "gpio10";
		function = "gpio";
		drive-strength = <2>;
		bias-disable;
	};

	gpio11_active: gpio11_active {
		pins = "gpio11";
		function = "gpio";
		drive-strength = <2>;
		bias-disable;
	};

	qup_uart2_rx: qup-uart2-rx-state {
		pins = "gpio11";
		function = "qup02";
		bias-disable;
	};

	gpio12_active: gpio12_active {
		pins = "gpio12";
		function = "gpio";
		drive-strength = <2>;
		bias-disable;
	};

	gpio24_active: gpio24_active {
		pins = "gpio24";
		function = "gpio";
		drive-strength = <2>;
		bias-disable;
	};

	gpio25_active: gpio25_active {
		pins = "gpio25";
		function = "gpio";
		drive-strength = <2>;
		bias-disable;
	};

	gpio24_active: gpio24_active {
		pins = "gpio24";
		function = "gpio";
		drive-strength = <2>;
		bias-disable;
	};

	gpio25_active: gpio25_active {
		pins = "gpio25";
		function = "gpio";
		drive-strength = <2>;
		bias-disable;
	};

	gpio26_active: gpio26_active {
		pins = "gpio26";
		function = "gpio";
		drive-strength = <2>;
		bias-disable;
	};

	gpio27_active: gpio27_active {
		pins = "gpio27";
		function = "gpio";
		drive-strength = <2>;
		bias-disable;
	};

	gpio32_active: gpio32_active {
		pins = "gpio32";
		function = "gpio";
		drive-strength = <2>;
		bias-disable;
	};

	gpio33_active: gpio33_active {
		pins = "gpio33";
		function = "gpio";
		drive-strength = <2>;
		bias-disable;
	};

	gpio34_active: gpio34_active {
		pins = "gpio34";
		function = "gpio";
		drive-strength = <2>;
		bias-disable;
	};

	gpio35_active: gpio35_active {
		pins = "gpio35";
		function = "gpio";
		drive-strength = <2>;
		bias-disable;
	};

	gpio44_active: gpio44_active {
		pins = "gpio44";
		function = "gpio";
		drive-strength = <2>;
		bias-disable;
	};

	gpio48_active: gpio48_active {
		pins = "gpio48";
		function = "gpio";
		drive-strength = <2>;
		bias-disable;
	};

	gpio49_active: gpio49_active {
		pins = "gpio49";
		function = "gpio";
		drive-strength = <2>;
		bias-disable;
	};

	gpio50_active: gpio50_active {
		pins = "gpio50";
		function = "gpio";
		drive-strength = <2>;
		bias-disable;
	};

	gpio51_active: gpio51_active {
		pins = "gpio51";
		function = "gpio";
		drive-strength = <2>;
		bias-disable;
	};

	gpio55_active: gpio55_active {
		pins = "gpio55";
		function = "gpio";
		drive-strength = <2>;
		bias-disable;
	};

	gpio101_active: gpio101_active {
		pins = "gpio101";
		function = "gpio";
		drive-strength = <2>;
		bias-disable;
	};

	gpio102_active: gpio102_active {
		pins = "gpio102";
		function = "gpio";
		drive-strength = <2>;
		bias-disable;
	};

	gpio103_active: gpio103_active {
		pins = "gpio103";
		function = "gpio";
		drive-strength = <2>;
		bias-disable;
	};

	gpio104_active: gpio104_active {
		pins = "gpio104";
		function = "gpio";
		drive-strength = <2>;
		bias-disable;
	};

	gpio105_active: gpio105_active {
		pins = "gpio105";
		function = "gpio";
		drive-strength = <2>;
		bias-disable;
	};

	pcie1_wake_n: pcie1-wake-n-state {
		pins = "gpio3";
		function = "gpio";
		drive-strength = <2>;
		bias-pull-up;
	};

	pcie1_clkreq_n: pcie1-clkreq-n-state {
		pins = "gpio79";
		function = "pcie1_clkreqn";
		drive-strength = <2>;
		bias-pull-up;
	};

	pcie1_reset_n: pcie1-reset-n-state {
		pins = "gpio2";
		function = "gpio";
		drive-strength = <16>;
		output-high;
		bias-disable;
	};

	mi2s2_data0: mi2s2-data0-state {
		pins = "gpio102";
		function = "mi2s2_data0";
	};

	mi2s2_data1: mi2s2-data1-state {
		pins = "gpio104";
		function = "mi2s2_data1";
	};

	mi2s2_sclk: mi2s2-sclk-state {
		pins = "gpio101";
		function = "mi2s2_sck";
	};

	mi2s2_ws: mi2s2-ws-state {
		pins = "gpio103";
		function = "mi2s2_ws";
	};

	mi2s2_data0_sleep: mi2s2-data0-sleep {
		pins = "gpio102";
		function = "gpio";
		drive-strength = <2>;
		bias-pull-down;
		input-enable;
	};

	mi2s2_data1_sleep: mi2s2-data1-sleep {
		pins = "gpio104";
		function = "gpio";
		drive-strength = <2>;
		bias-pull-down;
		input-enable;
	};

	mi2s2_sclk_sleep: mi2s2-sclk-sleep {
		pins = "gpio101";
		function = "gpio";
		drive-strength = <2>;
		bias-pull-down;
		input-enable;
	};

	mi2s2_ws_sleep: mi2s2-ws-sleep {
		pins = "gpio103";
		function = "gpio";
		drive-strength = <2>;
		bias-pull-down;
		input-enable;
	};

	mi2s1_data0_sleep: mi2s1-data0-sleep {
		pins = "gpio107";
		function = "gpio";
		drive-strength = <2>;
		bias-pull-down;
		input-enable;
	};

	mi2s1_data1_sleep: mi2s1-data1-sleep {
		pins = "gpio105";
		function = "gpio";
		drive-strength = <2>;
		bias-pull-down;
		input-enable;
	};

	mi2s1_sclk_sleep: mi2s1-sclk-sleep {
		pins = "gpio106";
		function = "gpio";
		drive-strength = <2>;
		bias-pull-down;
		input-enable;
	};

	mi2s1_ws_sleep: mi2s1-ws-sleep {
		pins = "gpio108";
		function = "gpio";
		drive-strength = <2>;
		bias-pull-down;
		input-enable;
	};

	mi2s1_data0: mi2s1-data0-state {
		pins = "gpio107";
		function = "mi2s1_data0";
	};

	mi2s1_data1: mi2s1-data1-state {
		pins = "gpio105";
		function = "mi2s1_data1";
	};

	mi2s1_sclk: mi2s1-sclk-state {
		pins = "gpio106";
		function = "mi2s1_sck";
	};

	mi2s1_ws: mi2s1-ws-state {
		pins = "gpio108";
		function = "mi2s1_ws";
	};

	wifi_reset_active: wifi_reset_active {
		pins = "gpio16";
		function = "gpio";
		drive-strength = <2>;
		output-high;
		bias-disable;
	};

	io_level_selection_3v3: io_level_selection_3v3 {
		pins = "gpio14";
		function = "gpio";
		drive-strength = <2>;
		output-high;
		bias-disable;
	};

	io_level_selection_5v0: io_level_selection_5v0 {
		pins = "gpio40";
		function = "gpio";
		drive-strength = <2>;
		output-high;
		bias-disable;
	};
};

&lpass_dmic01_clk {
	status = "disabled";
};

&lpass_dmic01_data {
	status = "disabled";
};

&lpass_dmic23_clk {
	status = "disabled";
};

&lpass_dmic23_data {
	status = "disabled";
};

&lpass_tlmm {
	/delete-node/ dmic45-data-state;
	/delete-node/ dmic45-clk-state;

	lpass_ext_mas_clk1_a: ext-master-clk1-a-state {
		pins = "gpio13";
		function = "ext_mas_clk1_a";
	};

	lpass_ext_mas_clk1_a_sleep: ext-master-clk1-a-sleep {
		pins = "gpio13";
		function = "ext_mas_clk1_a";
		drive-strength = <2>;
		bias-pull-down;
		input-enable;
	};

	lpass_qua_mi2s_sclk: qua-mi2s-sclk-state {
		pins = "gpio0";
		function = "qua_mi2s_sclk";
	};

	lpass_qua_mi2s_sclk_sleep: qua-mi2s-sclk-sleep {
		pins = "gpio0";
		function = "qua_mi2s_sclk";
		drive-strength = <2>;
		bias-pull-down;
		input-enable;
	};

	lpass_qua_mi2s_ws: qua-mi2s-ws-state {
		pins = "gpio1";
		function = "qua_mi2s_ws";
	};

	lpass_qua_mi2s_ws_sleep: qua-mi2s-ws-sleep {
		pins = "gpio1";
		function = "qua_mi2s_ws";
		drive-strength = <2>;
		bias-pull-down;
		input-enable;
	};

	lpass_qua_mi2s_data0: qua-mi2s-data0-state {
		pins = "gpio2";
		function = "qua_mi2s_data";
	};

	lpass_qua_mi2s_data0_sleep: qua-mi2s-data0-sleep {
		pins = "gpio2";
		function = "qua_mi2s_data";
		drive-strength = <2>;
		bias-pull-down;
		input-enable;
	};

	lpass_qua_mi2s_data1: qua-mi2s-data1-state {
		pins = "gpio3";
		function = "qua_mi2s_data";
	};

	lpass_qua_mi2s_data1_sleep: qua-mi2s-data1-sleep {
		pins = "gpio3";
		function = "qua_mi2s_data";
		drive-strength = <2>;
		bias-pull-down;
		input-enable;
	};

	lpass_qua_mi2s_data2: qua-mi2s-data2-state {
		pins = "gpio4";
		function = "qua_mi2s_data";
	};

	lpass_qua_mi2s_data2_sleep: qua-mi2s-data2-sleep {
		pins = "gpio4";
		function = "qua_mi2s_data";
		drive-strength = <2>;
		bias-pull-down;
		input-enable;
	};

	lpass_qua_mi2s_data3: qua-mi2s-data3-state {
		pins = "gpio5";
		function = "qua_mi2s_data";
	};

	lpass_qua_mi2s_data3_sleep: qua-mi2s-data3-sleep {
		pins = "gpio5";
		function = "qua_mi2s_data";
		drive-strength = <2>;
		bias-pull-down;
		input-enable;
	};

	lpass_lpi_i2s1_clk: lpi-i2s1-clk-state {
		pins = "gpio6";
		function = "i2s1_clk";
	};

	lpass_lpi_i2s1_ws: lpi-i2s1-ws-state {
		pins = "gpio7";
		function = "i2s1_ws";
	};

	lpass_lpi_i2s1_data0: lpi-i2s1-data0-state {
		pins = "gpio8";
		function = "i2s1_data";
	};

	lpass_lpi_i2s1_data1: lpi-i2s1-data1-state {
		pins = "gpio9";
		function = "i2s1_data";
	};

	lpass_lpi_i2s1_clk_sleep: lpi-i2s1-clk-sleep {
		pins = "gpio6";
		function = "i2s1_clk";
		drive-strength = <2>;
		bias-pull-down;
		input-enable;
	};

	lpass_lpi_i2s1_ws_sleep: lpi-i2s1-ws-sleep {
		pins = "gpio7";
		function = "i2s1_ws";
		drive-strength = <2>;
		bias-pull-down;
		input-enable;
	};

	lpass_lpi_i2s1_data0_sleep: lpi-i2s1-data0-sleep {
		pins = "gpio8";
		function = "i2s1_data";
		drive-strength = <2>;
		bias-pull-down;
		input-enable;
	};

	lpass_lpi_i2s1_data1_sleep: lpi-i2s1-data1-sleep {
		pins = "gpio9";
		function = "i2s1_data";
		drive-strength = <2>;
		bias-pull-down;
		input-enable;
	};
};

&soc {
	tca64_22_vreg: tca64_22_regulator {
		compatible = "regulator-fixed";
		regulator-name = "tca64_22_vreg";
		startup-delay-us = <1000>;
		enable-active-high;
	};

	retimer_1c_vreg: retimer_1c_regulator {
		compatible = "regulator-fixed";
		regulator-name = "retimer_1c_vreg";
		startup-delay-us = <1000>;
		enable-active-high;
	};
};

&gcc {
	protected-clocks = <GCC_QSPI_CNOC_PERIPH_AHB_CLK>, <GCC_QSPI_CORE_CLK>,
			<GCC_QSPI_CORE_CLK_SRC>, <GCC_CFG_NOC_LPASS_CLK>,
			<GCC_MSS_GPLL0_MAIN_DIV_CLK_SRC>, <GCC_MSS_CFG_AHB_CLK>,
			<GCC_MSS_OFFLINE_AXI_CLK>, <GCC_MSS_SNOC_AXI_CLK>,
			<GCC_MSS_Q6_MEMNOC_AXI_CLK>, <GCC_MSS_Q6SS_BOOT_CLK_SRC>,
			<GCC_SEC_CTRL_CLK_SRC>, <GCC_WPSS_AHB_CLK>,
			<GCC_WPSS_AHB_BDG_MST_CLK>, <GCC_WPSS_RSCP_CLK>;
};

&i2c0 {
	status = "ok";
	es8316: es8316@11 {
		compatible = "everest,es8316";
		reg = <0x11>;
		clocks = <&lpass_aon LPASS_AON_CC_TX_MCLK_CLK>;
        clock-names = "mclk";
		#sound-dai-cells = <0>;
		power_en-gpio = <&tlmm 117 0>;
		irq-gpio = <&tlmm 63 0>;
		status = "ok";
    };
};

&i2c1 {
	clock-frequency = <100000>;
	pinctrl-names = "default";
	pinctrl-0 = <&qup_i2c1_data_clk>;

	/delete-node/ typec-mux@42;

	typec-mux@42 {
		status = "disabled";
	};

	pm8008i@8 {
		status = "disabled";
	};

	pm8008i@9 {
		status = "disabled";
	};

	pm8008j@c {
		status = "disabled";
	};

	pm8008j@d {
		status = "disabled";
	};
};

&i2c2 {
	clock-frequency = <100000>;
	status = "okay";
};

&i2c12 {
	status = "disabled";
	tca64_22: tca6424@22 {
		compatible = "ti,tca6424";
		reg = <0x22>;
		vcc-supply = <&tca64_22_vreg>;
		gpio-controller;
		#gpio-cells = <2>;
	};
};

&i2c15 {
	status = "ok";
	husb238@8 {
		status = "ok";
		compatible = "husb238_pdc";
		reg = <0x08>;
	};
};

&uart4 {
	status = "disabled";
	pinctrl-0 = <&qup_uart4_tx>, <&qup_uart4_rx>;
};

&uart14 {
	status = "disabled";
};

&apps_rsc {
	regulators-0 {
		vreg_l2b_3p072: ldo2 {
			regulator-min-microvolt = <3100000>;
			regulator-max-microvolt = <3544000>;
			regulator-initial-mode = <RPMH_REGULATOR_MODE_HPM>;
		};

		vreg_l6b_1p2: ldo6 {
			regulator-min-microvolt = <1140000>;
			regulator-max-microvolt = <1260000>;
			regulator-initial-mode = <RPMH_REGULATOR_MODE_HPM>;
		};
	};

	regulators-1 {
		vreg_l1c_1p8: ldo1 {
			regulator-min-microvolt = <1800000>;
			regulator-max-microvolt = <1980000>;
			regulator-initial-mode = <RPMH_REGULATOR_MODE_HPM>;
		};

		vreg_l10c_0p88:ldo10 {
			regulator-min-microvolt = <880000>;
			regulator-max-microvolt = <1050000>;
			regulator-initial-mode = <RPMH_REGULATOR_MODE_HPM>;
		};

		vreg_l9c_2p96: ldo9 {
			regulator-min-microvolt = <2700000>;
			regulator-max-microvolt = <3544000>;
			regulator-initial-mode = <RPMH_REGULATOR_MODE_HPM>;
		};

		vreg_l6c_2p96: ldo6 {
			regulator-min-microvolt = <1800000>;
			regulator-max-microvolt = <1800000>;
			regulator-initial-mode = <RPMH_REGULATOR_MODE_HPM>;
			regulator-boot-on;
			regulator-enable-ramp-delay = <10000>;
		};
	};
};

&bluetooth {
	status = "disabled";
};

&pcie0_phy {
	status = "okay";
	qcom,refclk-always-on;
	vdda-phy-supply = <&vreg_l10c_0p88>;
	vdda-pll-supply = <&vreg_l6b_1p2>;
};

&pcie0 {
	status = "okay";
	vdda-supply = <&usb_hub0_rest_vreg>;
	pcieport0: pcie@0 {
		pcie0_bus1_dev0_fn0: pcie0_bus1_dev0_fn0 {
			reg = <0 0 0 0 0>;
		};
	};
};

&pcie1 {
	status = "okay";
	perst-gpios = <&tlmm 2 GPIO_ACTIVE_LOW>;
	vdda-supply = <&M2_1p8_vreg>;
	pinctrl-names = "default";
	pinctrl-0 = <&pcie1_clkreq_n>, <&pcie1_wake_n>;
	pcieport1: pcie@1 {
		device_type = "pci";
		reg = <0x0 0x0 0x0 0x0 0x0>;
		#address-cells = <5>;
		#size-cells = <0>;
		pcie1_bus1_dev0_fn0: pcie1_bus1_dev0_fn0 {
			reg = <0 0 0 0 0>;
		};
	};
};

&pcie1_phy {
	status = "okay";
	vdda-phy-supply = <&vreg_l10c_0p88>;
	vdda-pll-supply = <&vreg_l6b_1p2>;
	qcom,refclk-always-on;
};

&lpass_va_macro {
	pinctrl-0 = <&lpass_dmic01_clk>, <&lpass_dmic01_data>,
		    <&lpass_dmic23_clk>, <&lpass_dmic23_data>;
};

&lpass_rx_macro {
	status = "disabled";
};

&lpass_tx_macro {
	status = "disabled";
};

&lpass_wsa_macro {
	status = "disabled";
};

&lpass_va_macro {
	status = "disabled";
};

&swr2 {
	status = "disabled";
};

&wcd9370 {
	status = "disabled";
};

&swr0 {
	status = "disabled";
};

&swr1 {
	status = "disabled";
};

&remoteproc_adsp {
	firmware-name = "qcom/qcs6490/adsp.mdt";
	status = "okay";
};

&remoteproc_cdsp {
	firmware-name = "qcom/qcs6490/cdsp.mdt";
	status = "okay";
};

&remoteproc_mpss {
	firmware-name = "qcom/qcs6490/modem.mdt";
	status = "okay";
};

&remoteproc_wpss {
	firmware-name = "qcom/qcs6490/wpss.mdt";
	status = "okay";
};

&sound {
	pinctrl-names = "default", "stub_aif0_active", "stub_aif0_sleep";
	pinctrl-0 = <&mi2s0_data0_sleep>, <&mi2s0_data1_sleep>, <&mi2s0_mclk>,
	            <&mi2s0_sclk_sleep>, <&mi2s0_ws_sleep>,
	            <&lpass_ext_mas_clk1_a_sleep>, <&lpass_qua_mi2s_sclk_sleep>,
	            <&lpass_qua_mi2s_ws_sleep>, <&lpass_qua_mi2s_data0_sleep>,
	            <&lpass_qua_mi2s_data1_sleep>, <&lpass_qua_mi2s_data2_sleep>,
	            <&lpass_qua_mi2s_data3_sleep>, <&lpass_lpi_i2s1_clk_sleep>,
	            <&lpass_lpi_i2s1_ws_sleep>, <&lpass_lpi_i2s1_data0_sleep>,
	            <&lpass_lpi_i2s1_data1_sleep>, <&mi2s2_sclk_sleep>,
	            <&mi2s2_ws_sleep>, <&mi2s2_data0_sleep>, <&mi2s2_data1_sleep>;
	pinctrl-1 = <&mi2s0_data0>, <&mi2s0_data1>, <&mi2s0_mclk>,
	            <&mi2s0_sclk>, <&mi2s0_ws>,
	            <&lpass_ext_mas_clk1_a>, <&lpass_qua_mi2s_sclk>,
	            <&lpass_qua_mi2s_ws>, <&lpass_qua_mi2s_data0>,
	            <&lpass_qua_mi2s_data1>, <&lpass_qua_mi2s_data2>,
	            <&lpass_qua_mi2s_data3>, <&lpass_lpi_i2s1_clk>,
	            <&lpass_lpi_i2s1_ws>, <&lpass_lpi_i2s1_data0>,
	            <&lpass_lpi_i2s1_data1>, <&mi2s2_sclk>,
	            <&mi2s2_ws>, <&mi2s2_data0>, <&mi2s2_data1>;
	pinctrl-2 = <&mi2s0_data0_sleep>, <&mi2s0_data1_sleep>, <&mi2s0_mclk>,
	            <&mi2s0_sclk_sleep>, <&mi2s0_ws_sleep>,
	            <&lpass_ext_mas_clk1_a_sleep>, <&lpass_qua_mi2s_sclk_sleep>,
	            <&lpass_qua_mi2s_ws_sleep>, <&lpass_qua_mi2s_data0_sleep>,
	            <&lpass_qua_mi2s_data1_sleep>, <&lpass_qua_mi2s_data2_sleep>,
	            <&lpass_qua_mi2s_data3_sleep>, <&lpass_lpi_i2s1_clk_sleep>,
	            <&lpass_lpi_i2s1_ws_sleep>, <&lpass_lpi_i2s1_data0_sleep>,
	            <&lpass_lpi_i2s1_data1_sleep>, <&mi2s2_sclk_sleep>,
	            <&mi2s2_ws_sleep>, <&mi2s2_data0_sleep>, <&mi2s2_data1_sleep>;

	// audio-routing =
	// 	"VA DMIC0", "vdd-micb",
	// 	"VA DMIC1", "vdd-micb",
	// 	"VA DMIC2", "vdd-micb",
	// 	"VA DMIC3", "vdd-micb";

	/delete-node/ mi2s-playback-dai-link;
	/delete-node/ mi2s-capture-dai-link;
	/delete-node/ va-dai-link;

	mi2s-playback-dai-link {
		link-name = "MI2S-LPAIF-RX-PRIMARY";
		cpu {
			sound-dai = <&q6apmbedai PRIMARY_MI2S_RX>;
		};
		codec {
			sound-dai = <&msm_stub_codec 0>, <&es8316>;
		};
	};

	mi2s-capture-dai-link {
		link-name = "MI2S-LPAIF-TX-PRIMARY";
		cpu {
			sound-dai = <&q6apmbedai PRIMARY_MI2S_TX>;
		};
		codec {
			sound-dai = <&msm_stub_codec 1>, <&es8316>;
		};
	};

	quaternary-mi2s-playback-dai-link {
		link-name = "MI2S-LPAIF_RXTX-RX-PRIMARY";
		cpu {
			sound-dai = <&q6apmbedai QUATERNARY_MI2S_RX>;
		};
		codec {
			sound-dai = <&msm_stub_codec 0>;
		};
	};

	quaternary-mi2s-capture-dai-link {
		link-name = "MI2S-LPAIF_RXTX-TX-PRIMARY";
		cpu {
			sound-dai = <&q6apmbedai QUATERNARY_MI2S_TX>;
		};
		codec {
			sound-dai = <&msm_stub_codec 1>;
		};
	};

	quin-mi2s-playback-dai-link {
		link-name = "MI2S-LPAIF_VA-RX-PRIMARY";
		cpu {
			sound-dai = <&q6apmbedai QUINARY_MI2S_RX>;
		};
		codec {
			sound-dai = <&msm_stub_codec 0>;
		};
	};

	quin-mi2s-capture-dai-link {
		link-name = "MI2S-LPAIF_VA-TX-PRIMARY";
		cpu {
			sound-dai = <&q6apmbedai QUINARY_MI2S_TX>;
		};
		codec {
			sound-dai = <&msm_stub_codec 1>;
		};
	};

	tert-mi2s-playback-dai-link {
		link-name = "MI2S-LPAIF_AUD-RX-SECONDARY";
		cpu {
			sound-dai = <&q6apmbedai TERTIARY_MI2S_RX>;
		};
		codec {
			sound-dai = <&msm_stub_codec 0>;
		};
	};

	tert-mi2s-capture-dai-link {
		link-name = "MI2S-LPAIF_AUD-TX-SECONDARY";
		cpu {
			sound-dai = <&q6apmbedai TERTIARY_MI2S_TX>;
		};
		codec {
			sound-dai = <&msm_stub_codec 1>;
		};
	};

	/delete-node/ wsa-dai-link;
	/delete-node/ vi-feedback-dai-link;
	/delete-node/ wcd-playback-dai-link;
	/delete-node/ wcd-capture-dai-link;
};

&usb_1 {
	snps,dis-u2-entry-quirk;
	snps,dis-u1-entry-quirk;
};


&sdc2_clk {
	bias-disable;
	drive-strength = <16>;
};

&sdc2_cmd {
	bias-pull-up;
	drive-strength = <10>;
};

&sdc2_data {
	bias-pull-up;
	drive-strength = <10>;
};

&qup_uart7_rx {
	/delete-property/ bias-pull-up;
	bias-pull-down;
	output-low;
};

&sdhc_2 {
	status = "okay";

	pinctrl-0 = <&sdc2_clk>, <&sdc2_cmd>, <&sdc2_data>;
	pinctrl-1 = <&sdc2_clk_sleep>, <&sdc2_cmd_sleep>, <&sdc2_data_sleep>;
	vdda-supply = <&sdio_bt_reset_1p8_vreg>;

	gpio_bt_reg_on = <&tlmm 17 0>;

	non-removable;
	keep-power-in-suspend;

	/delete-property/ cd-gpios;
};

/delete-node/ &usb_2_dwc3;

&usb_2 {
	reg = <0x0 0x08c00000 0x0 0x100000>;

	interrupts-extended = <&intc GIC_SPI 242 IRQ_TYPE_LEVEL_HIGH>,
				<&intc GIC_SPI 240 IRQ_TYPE_LEVEL_HIGH>,
				<&pdc 12 IRQ_TYPE_LEVEL_HIGH>,
				<&pdc 13 IRQ_TYPE_EDGE_BOTH>;
	interrupt-names = "dwc_usb2",
			"hs_phy_irq",
			"dp_hs_phy_irq",
			"dm_hs_phy_irq";

	iommus = <&apps_smmu 0xa0 0x0>;
	snps,dis_u2_susphy_quirk;
	snps,dis_enblslpm_quirk;
	phys = <&usb_2_hsphy>;
	phy-names = "usb2-phy";
	maximum-speed = "high-speed";
	snps,dis-u2-entry-quirk;
	snps,dis-u1-entry-quirk;

	usb-role-switch;
	qcom,enable-rt;
	wakeup-source;
	dr_mode = "otg";
	role-switch-default-mode = "host";

	vdda-supply = <&usba_1p8_vreg>;

	status = "okay";

	ports {
		#address-cells = <1>;
		#size-cells = <0>;

		port@0 {
			usb2_role_switch: endpoint {
				remote-endpoint = <&eud_ep>;
			};
		};
	};
};

&usb_2_hsphy {
	vdda-pll-supply = <&vreg_l10c_0p88>;
	vdda18-supply = <&vreg_l1c_1p8>;
	vdda33-supply = <&vreg_l2b_3p072>;

	status = "okay";
};

&uart7 {
	status = "okay";
	/delete-property/interrupts;
	interrupts-extended = <&intc GIC_SPI 608 IRQ_TYPE_LEVEL_HIGH>,
				<&tlmm 31 IRQ_TYPE_EDGE_FALLING>;
	pinctrl-names = "default", "sleep";
	pinctrl-1 = <&qup_uart7_sleep_cts>, <&qup_uart7_sleep_rts>,
			<&qup_uart7_sleep_tx>, <&qup_uart7_sleep_rx>;
};

&pm8350c_gpios {
	fan_pwm_out_default: fan_pwm_out_default {
		pins = "gpio8";
		function = "func1";
		power-source = <1>;
		drive-push-pull;
		output-high;
		qcom,drive-strength = <3>;
	};
};

&thermal_zones {
	cpu0-thermal {
		trips {
			cpu0_alert2: trip-point2 {
				temperature = <60000>;
				hysteresis = <2000>;
				type = "passive";
			};

			cpu0_alert3: trip-point3 {
				temperature = <80000>;
				hysteresis = <2000>;
				type = "passive";
			};
		};

		cooling-maps {
			map2 {
				trip = <&cpu0_alert2 255>;
				cooling-device = <&fan0 1 1>;
			};

			map3 {
				trip = <&cpu0_alert3 255>;
				cooling-device = <&fan0 2 2>;
			};
		};
	};

	cpu1-thermal {
		trips {
			cpu1_alert2: trip-point2 {
				temperature = <60000>;
				hysteresis = <2000>;
				type = "passive";
			};

			cpu1_alert3: trip-point3 {
				temperature = <80000>;
				hysteresis = <2000>;
				type = "passive";
			};
		};

		cooling-maps {
			map2 {
				trip = <&cpu1_alert2 255>;
				cooling-device = <&fan0 1 1>;
			};

			map3 {
				trip = <&cpu1_alert3 255>;
				cooling-device = <&fan0 2 2>;
			};
		};
	};

	cpu2-thermal {
		trips {
			cpu2_alert2: trip-point2 {
				temperature = <60000>;
				hysteresis = <2000>;
				type = "passive";
			};

			cpu2_alert3: trip-point3 {
				temperature = <80000>;
				hysteresis = <2000>;
				type = "passive";
			};
		};

		cooling-maps {
			map2 {
				trip = <&cpu2_alert2 255>;
				cooling-device = <&fan0 1 1>;
			};

			map3 {
				trip = <&cpu2_alert3 255>;
				cooling-device = <&fan0 2 2>;
			};
		};
	};

	cpu3-thermal {
		trips {
			cpu3_alert2: trip-point2 {
				temperature = <60000>;
				hysteresis = <2000>;
				type = "passive";
			};

			cpu3_alert3: trip-point3 {
				temperature = <80000>;
				hysteresis = <2000>;
				type = "passive";
			};
		};

		cooling-maps {
			map2 {
				trip = <&cpu3_alert2 255>;
				cooling-device = <&fan0 1 1>;
			};

			map3 {
				trip = <&cpu3_alert3 255>;
				cooling-device = <&fan0 2 2>;
			};
		};
	};

	cpu4-thermal {
		trips {
			cpu4_alert2: trip-point2 {
				temperature = <60000>;
				hysteresis = <2000>;
				type = "passive";
			};

			cpu4_alert3: trip-point3 {
				temperature = <80000>;
				hysteresis = <2000>;
				type = "passive";
			};
		};

		cooling-maps {
			map2 {
				trip = <&cpu4_alert2 255>;
				cooling-device = <&fan0 1 1>;
			};

			map3 {
				trip = <&cpu4_alert3 255>;
				cooling-device = <&fan0 2 2>;
			};
		};
	};

	cpu5-thermal {
		trips {
			cpu5_alert2: trip-point2 {
				temperature = <60000>;
				hysteresis = <2000>;
				type = "passive";
			};

			cpu5_alert3: trip-point3 {
				temperature = <80000>;
				hysteresis = <2000>;
				type = "passive";
			};
		};

		cooling-maps {
			map2 {
				trip = <&cpu5_alert2 255>;
				cooling-device = <&fan0 1 1>;
			};

			map3 {
				trip = <&cpu5_alert3 255>;
				cooling-device = <&fan0 2 2>;
			};
		};
	};

	cpu6-thermal {
		trips {
			cpu6_alert2: trip-point2 {
				temperature = <60000>;
				hysteresis = <2000>;
				type = "passive";
			};

			cpu6_alert3: trip-point3 {
				temperature = <80000>;
				hysteresis = <2000>;
				type = "passive";
			};
		};

		cooling-maps {
			map2 {
				trip = <&cpu6_alert2 255>;
				cooling-device = <&fan0 1 1>;
			};

			map3 {
				trip = <&cpu6_alert3 255>;
				cooling-device = <&fan0 2 2>;
			};
		};
	};

	cpu7-thermal {
		trips {
			cpu7_alert2: trip-point2 {
				temperature = <60000>;
				hysteresis = <2000>;
				type = "passive";
			};

			cpu7_alert3: trip-point3 {
				temperature = <80000>;
				hysteresis = <2000>;
				type = "passive";
			};
		};

		cooling-maps {
			map2 {
				trip = <&cpu7_alert2 255>;
				cooling-device = <&fan0 1 1>;
			};

			map3 {
				trip = <&cpu7_alert3 255>;
				cooling-device = <&fan0 2 2>;
			};
		};
	};
};

&pm8350c_pwm {
	/delete-property/ pinctrl-0;
	/delete-property/ pinctrl-names;

	led@2 {
		reg = <2>;
		color = <LED_COLOR_ID_GREEN>;
		label = "green";
	};
};

&pmk8350_rtc {
	status = "okay";
	allow-set-time;
};

&qup_i2c0_data_clk{
	bias-disable;
};

&qup_i2c15_data_clk{
	bias-disable;
};

/ {
	/delete-node/ regulator-lcd-disp-bias;

	hdmi-connector {
		compatible = "hdmi-connector";
		type = "a";

		port {
			hdmi_con: endpoint {
				remote-endpoint = <&lt9611_out>;
			};
		};
	};
};

&soc {
	lt9611_3p3_vreg: lt9611-3p3-vreg {
		compatible = "regulator-fixed";
		regulator-name = "lt9611_3p3_vreg";
		gpio = <&tlmm 83 0>;
		regulator-min-microvolt = <3300000>;
		regulator-max-microvolt = <3300000>;
		enable-active-high;
		regulator-enable-ramp-delay = <10000>;
	};
};

&apps_rsc {
	regulators-0 {
		vreg_l6b_1p2: ldo6 {
			regulator-min-microvolt = <1140000>;
			regulator-max-microvolt = <1260000>;
			regulator-initial-mode = <RPMH_REGULATOR_MODE_HPM>;
		};
	};

	regulators-1 {
		vreg_l10c_0p88: ldo10 {
			regulator-min-microvolt = <880000>;
			regulator-max-microvolt = <1050000>;
			regulator-initial-mode = <RPMH_REGULATOR_MODE_HPM>;
		};
	};
};

&pm7250b_gpios {
	/delete-node/ lcd-disp-bias-en-state;
};

&i2c9 {
	status = "okay";

	lt9611_codec: hdmi-bridge@39 {
		compatible = "lontium,lt9611";
		reg = <0x39>;

		interrupts-extended = <&tlmm 20 IRQ_TYPE_EDGE_BOTH>;
		reset-gpios = <&tlmm 21 0>;
		enable-gpios = <&tlmm 40 0>;
		ocb-gpios = <&tlmm 41 0>;
		vcc-supply = <&lt9611_3p3_vreg>;
		config-mode = "edidAdaptiveResolution";

		ports {
			#address-cells = <1>;
			#size-cells = <0>;

			port@0 {
				reg = <0>;

				lt9611_a: endpoint {
					remote-endpoint = <&mdss_dsi0_out>;
				};
			};

			port@2 {
				reg = <2>;

				lt9611_out: endpoint {
					remote-endpoint = <&hdmi_con>;
				};
			};
		};
	};
};

&mdss {
	status = "okay";
};

&mdss_dsi {
	vdda-supply = <&vreg_l6b_1p2>;
	status = "okay";

	/delete-node/ panel@0;
};

&mdss_dsi0_out {
	remote-endpoint = <&lt9611_a>;
	data-lanes = <0 1 2 3>;
};

&mdss_dsi_phy {
	vdds-supply = <&vreg_l10c_0p88>;
	status = "okay";
};

/ {
	model = "Thundercomm, Inc. RUBIK Pi 3";
	compatible = "qcom,qcm6490-addons-idp","qcom,sc7280";

	/* This will be deprecated soon */
	qcom,msm-id = <497 0x10000>, <498 0x10000>, <475 0x10000>, <515 0x10000>;
	qcom,board-id = <32 0xb>, <32 0x60b>;
};

&uart2 {
	status = "okay";
};

&i2c1 {
	status = "okay";

	rpi-sense@46 {
		compatible = "rpi,rpi-sense";
		reg = <0x46>;
		keys-int-gpios = <&tlmm 26 1>;
		status = "okay";
	};

	lsm9ds1-magn@1c {
		compatible = "st,lsm9ds1-magn";
		reg = <0x1c>;
		status = "okay";
	};

	lps25h-press@5c {
		compatible = "st,lps25h-press";
		reg = <0x5c>;
		status = "okay";
	};

	hts221-humid@5f {
		compatible = "st,hts221-humid", "st,hts221";
		reg = <0x5f>;
		status = "okay";
	};

	lsm9ds1-accel@6a {
		compatible = "st,lsm9ds1-accel";
		reg = <0x6a>;
		status = "okay";
	};
};

&spi12 {
	status = "okay";
	spidev@0 {
		compatible = "qcom,spidev";
		spi-max-frequency = <50000000>;
		reg = <0>;
	};
};
